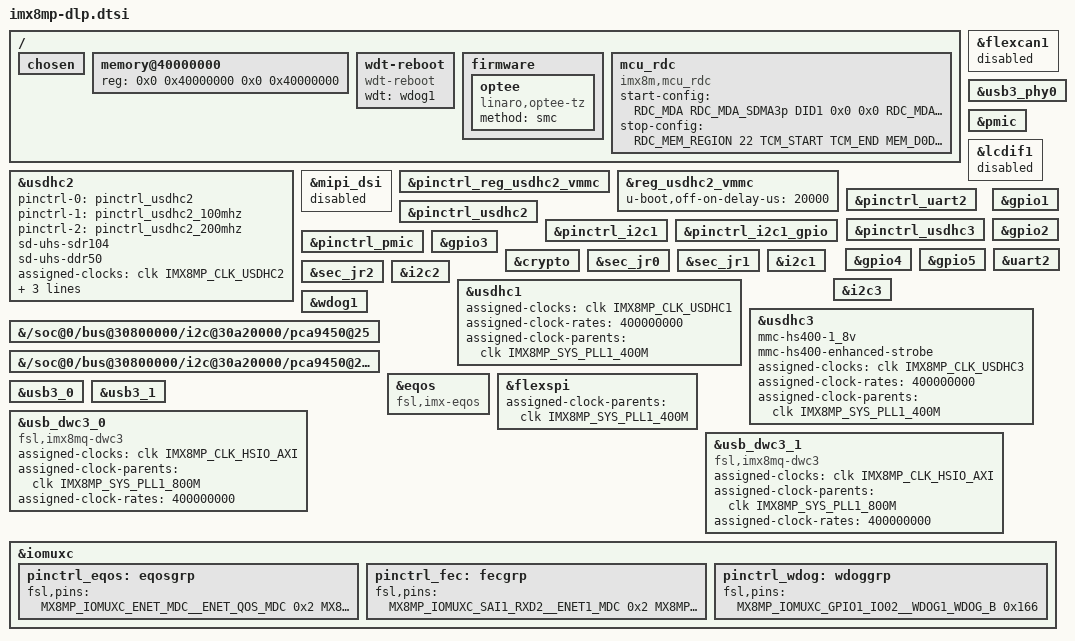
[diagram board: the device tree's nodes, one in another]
// SPDX-License-Identifier: GPL-2.0+
// Common DLP overrides applied on top of the patched imx8mp-evk.dts.
// Covers memory/peripheral corrections, DLP-specific pad configs,
// and U-Boot SPL/DM annotations shared by all DLP boards.

#include "imx8mp-sec-def.h"
#include "imx8mp-u-boot.dtsi"

/ {
	chosen {
		/delete-property/ bootargs;
	};

	memory@40000000 {
		reg = <0x0 0x40000000 0x0 0x40000000>;
	};

	wdt-reboot {
		compatible = "wdt-reboot";
		wdt = <&wdog1>;
		u-boot,dm-spl;
	};

	firmware {
		optee {
			compatible = "linaro,optee-tz";
			method = "smc";
		};
	};

	mcu_rdc {
		compatible = "imx8m,mcu_rdc";
		start-config = <
			RDC_MDA  RDC_MDA_SDMA3p DID1 0x0 0x0
			RDC_MDA  RDC_MDA_ENET1_TX DID1 0x0 0x0
			RDC_MDA  RDC_MDA_ENET1_RX DID1 0x0 0x0
			RDC_MDA  RDC_MDA_SDMA3b DID1 0x0 0x0
			RDC_MDA  RDC_MDA_SDMA3_SPBA2 DID1 0x0 0x0
			RDC_PDAP RDC_PDAP_ENET1 PDAP_D0D1_ACCESS 0x0 0x0
			RDC_PDAP RDC_PDAP_SAI3  PDAP_D1_ACCESS 0x0 0x0
			RDC_PDAP RDC_PDAP_UART4 PDAP_D1_ACCESS 0x0 0x0
			RDC_PDAP RDC_PDAP_GPT1  PDAP_D1_ACCESS 0x0 0x0
			RDC_PDAP RDC_PDAP_SDMA3 PDAP_D1_ACCESS 0x0 0x0
			RDC_PDAP RDC_PDAP_I2C3  PDAP_D1_ACCESS 0x0 0x0
			RDC_MEM_REGION 22 TCM_START TCM_END MEM_D1_ACCESS
			RDC_MEM_REGION 39 M4_DDR_START M4_DDR_END MEM_D1_ACCESS
			0x0      0x0            0x0  0x0 0x0
		>;
		stop-config = <
			RDC_MEM_REGION 22 TCM_START TCM_END MEM_D0D1_ACCESS
			RDC_MEM_REGION 39 M4_DDR_START M4_DDR_END MEM_D0D1_ACCESS
			0x0      0x0            0x0  0x0 0x0
		>;
	};
};

&flexcan1 {
	status = "disabled";
};

&usb3_phy0 {
	/delete-property/ vbus-power-supply;
};

&pmic {
	pinctrl-names = "default";
};

/* SD2_CD_B is repurposed as board-ID GPIO on DLP boards.
 * Patch 0006 emptied pinctrl_usdhc2_gpio leaving an invalid fsl,pins = <>.
 * Drop the stale cd-gpios and the broken pinctrl group from usdhc2. */
&usdhc2 {
	pinctrl-0 = <&pinctrl_usdhc2>;
	pinctrl-1 = <&pinctrl_usdhc2_100mhz>;
	pinctrl-2 = <&pinctrl_usdhc2_200mhz>;
	/delete-property/ cd-gpios;
};

&lcdif1  { status = "disabled"; };
&mipi_dsi { status = "disabled"; };

/* ---- U-Boot SPL / Driver-Model annotations ---- */

&pinctrl_reg_usdhc2_vmmc	{ u-boot,dm-spl; };
&reg_usdhc2_vmmc		{ u-boot,dm-spl; u-boot,off-on-delay-us = <20000>; };

&pinctrl_uart2			{ u-boot,dm-spl; };
/* pinctrl_usdhc2_gpio intentionally not annotated — node has invalid
   empty fsl,pins from patch 0006 and is dropped from usdhc2 pinctrl-*. */
&pinctrl_usdhc2			{ u-boot,dm-spl; };
&pinctrl_usdhc3			{ u-boot,dm-spl; };
&pinctrl_i2c1			{ u-boot,dm-spl; };
&pinctrl_i2c1_gpio		{ u-boot,dm-spl; };
&pinctrl_pmic			{ u-boot,dm-spl; };

&gpio1				{ u-boot,dm-spl; };
&gpio2				{ u-boot,dm-spl; };
&gpio3				{ u-boot,dm-spl; };
&gpio4				{ u-boot,dm-spl; };
&gpio5				{ u-boot,dm-spl; };

&uart2				{ u-boot,dm-spl; };

&crypto				{ u-boot,dm-spl; };
&sec_jr0			{ u-boot,dm-spl; };
&sec_jr1			{ u-boot,dm-spl; };
&sec_jr2			{ u-boot,dm-spl; };

&i2c1				{ u-boot,dm-spl; };
&i2c2				{ u-boot,dm-spl; };
&i2c3				{ u-boot,dm-spl; };

&usdhc1 {
	u-boot,dm-spl;
	assigned-clocks = <&clk IMX8MP_CLK_USDHC1>;
	assigned-clock-rates = <400000000>;
	assigned-clock-parents = <&clk IMX8MP_SYS_PLL1_400M>;
};

&usdhc2 {
	u-boot,dm-spl;
	sd-uhs-sdr104;
	sd-uhs-ddr50;
	assigned-clocks = <&clk IMX8MP_CLK_USDHC2>;
	assigned-clock-rates = <400000000>;
	assigned-clock-parents = <&clk IMX8MP_SYS_PLL1_400M>;
};

&usdhc3 {
	u-boot,dm-spl;
	mmc-hs400-1_8v;
	mmc-hs400-enhanced-strobe;
	assigned-clocks = <&clk IMX8MP_CLK_USDHC3>;
	assigned-clock-rates = <400000000>;
	assigned-clock-parents = <&clk IMX8MP_SYS_PLL1_400M>;
};

&wdog1				{ u-boot,dm-spl; };

/*
 * NOTE: U-Boot's EVK base DTS names the PMIC node pca9450@25 (label `pmic`),
 * while the kernel uses pmic@25. Reference by absolute path here so SPL
 * marks both the PMIC and its regulators for early probe.
 */
&{/soc@0/bus@30800000/i2c@30a20000/pca9450@25}			{ u-boot,dm-spl; };
&{/soc@0/bus@30800000/i2c@30a20000/pca9450@25/regulators}	{ u-boot,dm-spl; };

/* ---- U-Boot driver compat / clock cleanup ---- */

&eqos {
	compatible = "fsl,imx-eqos";
	/delete-property/ assigned-clocks;
	/delete-property/ assigned-clock-parents;
	/delete-property/ assigned-clock-rates;
};

&flexspi {
	assigned-clock-parents = <&clk IMX8MP_SYS_PLL1_400M>;
};

&lcdif1 {
	/delete-property/ assigned-clocks;
	/delete-property/ assigned-clock-parents;
	/delete-property/ assigned-clock-rates;
};

&mipi_dsi {
	/delete-property/ assigned-clocks;
	/delete-property/ assigned-clock-parents;
	/delete-property/ assigned-clock-rates;
};

&usb3_0 { /delete-property/ power-domains; };
&usb3_1 { /delete-property/ power-domains; };

&usb_dwc3_0 {
	compatible = "fsl,imx8mq-dwc3", "snps,dwc3";
	assigned-clocks = <&clk IMX8MP_CLK_HSIO_AXI>;
	assigned-clock-parents = <&clk IMX8MP_SYS_PLL1_800M>;
	assigned-clock-rates = <400000000>;
};

&usb_dwc3_1 {
	compatible = "fsl,imx8mq-dwc3", "snps,dwc3";
	assigned-clocks = <&clk IMX8MP_CLK_HSIO_AXI>;
	assigned-clock-parents = <&clk IMX8MP_SYS_PLL1_800M>;
	assigned-clock-rates = <400000000>;
};

/* ---- DLP-specific pinctrl pad configs ---- */

&iomuxc {
	pinctrl_eqos: eqosgrp {
		fsl,pins = <
			MX8MP_IOMUXC_ENET_MDC__ENET_QOS_MDC				0x2
			MX8MP_IOMUXC_ENET_MDIO__ENET_QOS_MDIO				0x2
			MX8MP_IOMUXC_ENET_RD0__ENET_QOS_RGMII_RD0			0x91
			MX8MP_IOMUXC_ENET_RD1__ENET_QOS_RGMII_RD1			0x91
			MX8MP_IOMUXC_ENET_RD2__ENET_QOS_RGMII_RD2			0x91
			MX8MP_IOMUXC_ENET_RD3__ENET_QOS_RGMII_RD3			0x91
			MX8MP_IOMUXC_ENET_RXC__CCM_ENET_QOS_CLOCK_GENERATE_RX_CLK	0x91
			MX8MP_IOMUXC_ENET_RX_CTL__ENET_QOS_RGMII_RX_CTL			0x91
			MX8MP_IOMUXC_ENET_TD0__ENET_QOS_RGMII_TD0			0x16
			MX8MP_IOMUXC_ENET_TD1__ENET_QOS_RGMII_TD1			0x16
			MX8MP_IOMUXC_ENET_TD2__ENET_QOS_RGMII_TD2			0x16
			MX8MP_IOMUXC_ENET_TD3__ENET_QOS_RGMII_TD3			0x16
			MX8MP_IOMUXC_ENET_TX_CTL__ENET_QOS_RGMII_TX_CTL			0x16
			MX8MP_IOMUXC_ENET_TXC__CCM_ENET_QOS_CLOCK_GENERATE_TX_CLK	0x16
		>;
	};

	pinctrl_fec: fecgrp {
		fsl,pins = <
			MX8MP_IOMUXC_SAI1_RXD2__ENET1_MDC		0x2
			MX8MP_IOMUXC_SAI1_RXD3__ENET1_MDIO		0x2
			MX8MP_IOMUXC_SAI1_RXD4__ENET1_RGMII_RD0		0x91
			MX8MP_IOMUXC_SAI1_RXD5__ENET1_RGMII_RD1		0x91
			MX8MP_IOMUXC_SAI1_RXD6__ENET1_RGMII_RD2		0x91
			MX8MP_IOMUXC_SAI1_RXD7__ENET1_RGMII_RD3		0x91
			MX8MP_IOMUXC_SAI1_TXC__ENET1_RGMII_RXC		0x91
			MX8MP_IOMUXC_SAI1_TXFS__ENET1_RGMII_RX_CTL	0x91
			MX8MP_IOMUXC_SAI1_TXD0__ENET1_RGMII_TD0		0x16
			MX8MP_IOMUXC_SAI1_TXD1__ENET1_RGMII_TD1		0x16
			MX8MP_IOMUXC_SAI1_TXD2__ENET1_RGMII_TD2		0x16
			MX8MP_IOMUXC_SAI1_TXD3__ENET1_RGMII_TD3		0x16
			MX8MP_IOMUXC_SAI1_TXD4__ENET1_RGMII_TX_CTL	0x16
			MX8MP_IOMUXC_SAI1_TXD5__ENET1_RGMII_TXC		0x16
			MX8MP_IOMUXC_SAI1_RXD0__GPIO4_IO02		0x10
		>;
	};

	pinctrl_wdog: wdoggrp {
		fsl,pins = <
			MX8MP_IOMUXC_GPIO1_IO02__WDOG1_WDOG_B	0x166
		>;
	};
};
